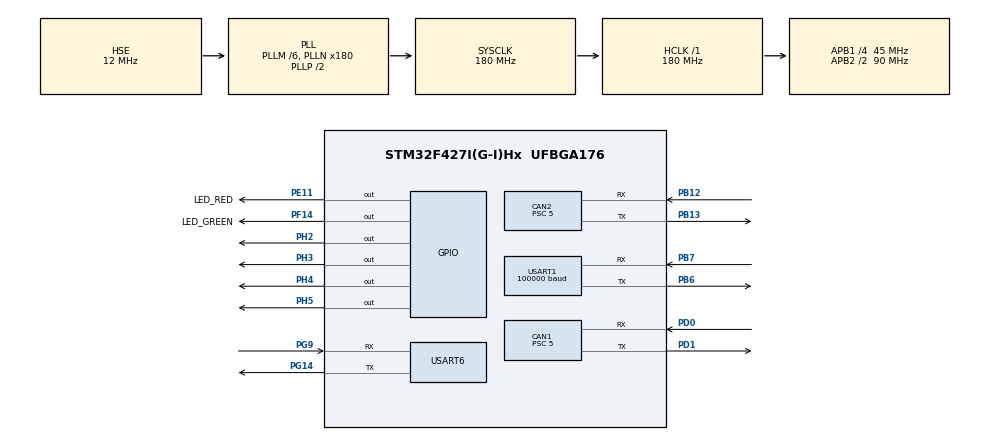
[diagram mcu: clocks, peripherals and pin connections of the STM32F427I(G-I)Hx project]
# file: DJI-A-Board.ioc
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CAN1.ABOM=ENABLE
CAN1.BS1=CAN_BS1_3TQ
CAN1.BS2=CAN_BS2_5TQ
CAN1.CalculateBaudRate=1000000
CAN1.CalculateTimeBit=1000
CAN1.CalculateTimeQuantum=111.11111111111111
CAN1.Prescaler=5
CAN2.ABOM=ENABLE
CAN2.BS1=CAN_BS1_3TQ
CAN2.BS2=CAN_BS2_5TQ
CAN2.CalculateBaudRate=1000000
CAN2.CalculateTimeBit=1000
CAN2.CalculateTimeQuantum=111.11111111111111
CAN2.Prescaler=5
Dma.Request0=USART1_RX
Dma.Request1=USART6_RX
Dma.Request2=USART6_TX
Dma.USART1_RX.0.Direction=DMA_PERIPH_TO_MEMORY
Dma.USART1_RX.0.FIFOMode=DMA_FIFOMODE_DISABLE
Dma.USART1_RX.0.Instance=DMA2_Stream2
Dma.USART1_RX.0.MemDataAlignment=DMA_MDATAALIGN_BYTE
Dma.USART1_RX.0.MemInc=DMA_MINC_ENABLE
Dma.USART1_RX.0.Mode=DMA_CIRCULAR
Dma.USART1_RX.0.PeriphDataAlignment=DMA_PDATAALIGN_BYTE
Dma.USART1_RX.0.PeriphInc=DMA_PINC_DISABLE
Dma.USART1_RX.0.Priority=DMA_PRIORITY_LOW
Dma.USART6_RX.1.Direction=DMA_PERIPH_TO_MEMORY
Dma.USART6_RX.1.FIFOMode=DMA_FIFOMODE_DISABLE
Dma.USART6_RX.1.Instance=DMA2_Stream1
Dma.USART6_RX.1.MemDataAlignment=DMA_MDATAALIGN_BYTE
Dma.USART6_RX.1.MemInc=DMA_MINC_ENABLE
Dma.USART6_RX.1.Mode=DMA_NORMAL
Dma.USART6_RX.1.PeriphDataAlignment=DMA_PDATAALIGN_BYTE
Dma.USART6_RX.1.PeriphInc=DMA_PINC_DISABLE
Dma.USART6_RX.1.Priority=DMA_PRIORITY_LOW
Dma.USART6_TX.2.Direction=DMA_MEMORY_TO_PERIPH
Dma.USART6_TX.2.FIFOMode=DMA_FIFOMODE_DISABLE
Dma.USART6_TX.2.Instance=DMA2_Stream6
Dma.USART6_TX.2.MemDataAlignment=DMA_MDATAALIGN_BYTE
Dma.USART6_TX.2.MemInc=DMA_MINC_ENABLE
Dma.USART6_TX.2.Mode=DMA_NORMAL
Dma.USART6_TX.2.PeriphDataAlignment=DMA_PDATAALIGN_BYTE
Dma.USART6_TX.2.PeriphInc=DMA_PINC_DISABLE
Dma.USART6_TX.2.Priority=DMA_PRIORITY_LOW
Mcu.Family=STM32F4
Mcu.Name=STM32F427I(G-I)Hx
Mcu.Package=UFBGA176
NVIC.CAN1_RX0_IRQn=true\:0\:0\:false\:false\:true\:true\:true\:true
NVIC.CAN2_RX0_IRQn=true\:0\:0\:false\:false\:true\:true\:true\:true
NVIC.DMA2_Stream1_IRQn=true\:0\:0\:false\:false\:true\:false\:true\:true
NVIC.DMA2_Stream2_IRQn=true\:0\:0\:false\:false\:true\:false\:true\:true
NVIC.DMA2_Stream6_IRQn=true\:0\:0\:false\:false\:true\:false\:true\:true
NVIC.PriorityGroup=NVIC_PRIORITYGROUP_4
NVIC.USART1_IRQn=true\:0\:0\:false\:false\:true\:true\:true\:true
NVIC.USART6_IRQn=true\:0\:0\:false\:false\:true\:true\:true\:true
PA13.Mode=Serial_Wire
PA13.Signal=SYS_JTMS-SWDIO
PA14.Mode=Serial_Wire
PA14.Signal=SYS_JTCK-SWCLK
PB12.Mode=CAN_Activate
PB12.Signal=CAN2_RX
PB13.Mode=CAN_Activate
PB13.Signal=CAN2_TX
PB6.GPIO_PuPd=GPIO_NOPULL
PB6.Mode=Asynchronous
PB6.Signal=USART1_TX
PB7.GPIO_PuPd=GPIO_NOPULL
PB7.Mode=Asynchronous
PB7.Signal=USART1_RX
PD0.Mode=CAN_Activate
PD0.Signal=CAN1_RX
PD1.Mode=CAN_Activate
PD1.Signal=CAN1_TX
PE11.GPIO_Label=LED_RED
PE11.GPIO_PuPd=GPIO_PULLUP
PE11.PinState=GPIO_PIN_SET
PE11.Signal=GPIO_Output
PF14.GPIO_Label=LED_GREEN
PF14.GPIO_PuPd=GPIO_PULLUP
PF14.PinState=GPIO_PIN_SET
PF14.Signal=GPIO_Output
PG14.GPIO_PuPd=GPIO_NOPULL
PG14.Mode=Asynchronous
PG14.Signal=USART6_TX
PG9.GPIO_PuPd=GPIO_NOPULL
PG9.Mode=Asynchronous
PG9.Signal=USART6_RX
PH0/OSC_IN.Mode=HSE-External-Oscillator
PH0/OSC_IN.Signal=RCC_OSC_IN
PH1/OSC_OUT.Mode=HSE-External-Oscillator
PH1/OSC_OUT.Signal=RCC_OSC_OUT
PH2.GPIO_PuPd=GPIO_PULLUP
PH2.PinState=GPIO_PIN_SET
PH2.Signal=GPIO_Output
PH3.GPIO_PuPd=GPIO_PULLUP
PH3.PinState=GPIO_PIN_SET
PH3.Signal=GPIO_Output
PH4.GPIO_PuPd=GPIO_PULLUP
PH4.PinState=GPIO_PIN_SET
PH4.Signal=GPIO_Output
PH5.GPIO_PuPd=GPIO_PULLUP
PH5.PinState=GPIO_PIN_SET
PH5.Signal=GPIO_Output
ProjectManager.HeapSize=0x200
ProjectManager.StackSize=0x400
ProjectManager.TargetToolchain=STM32CubeIDE
RCC.48MHZClocksFreq_Value=90000000
RCC.AHBFreq_Value=180000000
RCC.APB1CLKDivider=RCC_HCLK_DIV4
RCC.APB1Freq_Value=45000000
RCC.APB1TimFreq_Value=90000000
RCC.APB2CLKDivider=RCC_HCLK_DIV2
RCC.APB2Freq_Value=90000000
RCC.APB2TimFreq_Value=180000000
RCC.CortexFreq_Value=180000000
RCC.HCLKFreq_Value=180000000
RCC.HSE_VALUE=12000000
RCC.HSI_VALUE=16000000
RCC.LSE_VALUE=32768
RCC.PLLM=6
RCC.PLLN=180
RCC.PLLSourceVirtual=RCC_PLLSOURCE_HSE
RCC.SYSCLKFreq_VALUE=180000000
RCC.SYSCLKSource=RCC_SYSCLKSOURCE_PLLCLK
RCC.VCOOutputFreq_Value=360000000
TIM14.Period=10000-1
TIM14.Prescaler=45000-1
USART1.BaudRate=100000
USART1.Mode=MODE_TX_RX
USART1.Parity=PARITY_EVEN
USART1.VirtualMode=VM_ASYNC
USART6.VirtualMode=VM_ASYNC
VP_TIM14_VS_ClockSourceINT.Mode=Enable_Timer
board=custom

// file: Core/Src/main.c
/* USER CODE BEGIN Header */
/**
  ******************************************************************************
  * @file           : main.c
  * @brief          : Main program body
  ******************************************************************************
  * @attention
  *
  * Copyright (c) 2025 STMicroelectronics.
  * All rights reserved.
  *
  * This software is licensed under terms that can be found in the LICENSE file
  * in the root directory of this software component.
  * If no LICENSE file comes with this software, it is provided AS-IS.
  *
  ******************************************************************************
  */
/* USER CODE END Header */
#include "main.h"

/* USER CODE BEGIN Includes */
#include  "bsp.h"
#include <stdio.h>

/* USER CODE END Includes */

CAN_HandleTypeDef hcan1;
CAN_HandleTypeDef hcan2;

TIM_HandleTypeDef htim14;

UART_HandleTypeDef huart1;
UART_HandleTypeDef huart6;
DMA_HandleTypeDef hdma_usart1_rx;
DMA_HandleTypeDef hdma_usart6_rx;
DMA_HandleTypeDef hdma_usart6_tx;

void SystemClock_Config(void);
static void MX_GPIO_Init(void);
static void MX_DMA_Init(void);
static void MX_USART1_UART_Init(void);
static void MX_USART6_UART_Init(void);
static void MX_CAN1_Init(void);
static void MX_TIM14_Init(void);
static void MX_CAN2_Init(void);

int main(void)
{

  /* MCU Configuration--------------------------------------------------------*/

  /* Reset of all peripherals, Initializes the Flash interface and the Systick. */
  HAL_Init();

  /* Configure the system clock */
  SystemClock_Config();

  /* Initialize all configured peripherals */
  MX_GPIO_Init();
  MX_DMA_Init();
  MX_USART1_UART_Init();
  MX_USART6_UART_Init();
  MX_CAN1_Init();
  MX_TIM14_Init();
  MX_CAN2_Init();

  /* Infinite loop */
  while (1)
  {

    /* USER CODE BEGIN 3 */
    LOOP_EVENT_Handle();
  }
  /* USER CODE END 3 */
}

void SystemClock_Config(void)
{
  RCC_OscInitTypeDef RCC_OscInitStruct = {0};
  RCC_ClkInitTypeDef RCC_ClkInitStruct = {0};

  /** Configure the main internal regulator output voltage
  */
  __HAL_RCC_PWR_CLK_ENABLE();
  __HAL_PWR_VOLTAGESCALING_CONFIG(PWR_REGULATOR_VOLTAGE_SCALE1);

  /** Initializes the RCC Oscillators according to the specified parameters
  * in the RCC_OscInitTypeDef structure.
  */
  RCC_OscInitStruct.OscillatorType = RCC_OSCILLATORTYPE_HSE;
  RCC_OscInitStruct.HSEState = RCC_HSE_ON;
  RCC_OscInitStruct.PLL.PLLState = RCC_PLL_ON;
  RCC_OscInitStruct.PLL.PLLSource = RCC_PLLSOURCE_HSE;
  RCC_OscInitStruct.PLL.PLLM = 6;
  RCC_OscInitStruct.PLL.PLLN = 180;
  RCC_OscInitStruct.PLL.PLLP = RCC_PLLP_DIV2;
  RCC_OscInitStruct.PLL.PLLQ = 4;
  if (HAL_RCC_OscConfig(&RCC_OscInitStruct) != HAL_OK)
  {
    Error_Handler();
  }

  /** Activate the Over-Drive mode
  */
  if (HAL_PWREx_EnableOverDrive() != HAL_OK)
  {
    Error_Handler();
  }

  /** Initializes the CPU, AHB and APB buses clocks
  */
  RCC_ClkInitStruct.ClockType = RCC_CLOCKTYPE_HCLK|RCC_CLOCKTYPE_SYSCLK
                              |RCC_CLOCKTYPE_PCLK1|RCC_CLOCKTYPE_PCLK2;
  RCC_ClkInitStruct.SYSCLKSource = RCC_SYSCLKSOURCE_PLLCLK;
  RCC_ClkInitStruct.AHBCLKDivider = RCC_SYSCLK_DIV1;
  RCC_ClkInitStruct.APB1CLKDivider = RCC_HCLK_DIV4;
  RCC_ClkInitStruct.APB2CLKDivider = RCC_HCLK_DIV2;

  if (HAL_RCC_ClockConfig(&RCC_ClkInitStruct, FLASH_LATENCY_5) != HAL_OK)
  {
    Error_Handler();
  }
}

static void MX_CAN1_Init(void)
{

  hcan1.Instance = CAN1;
  hcan1.Init.Prescaler = 5;
  hcan1.Init.Mode = CAN_MODE_NORMAL;
  hcan1.Init.SyncJumpWidth = CAN_SJW_1TQ;
  hcan1.Init.TimeSeg1 = CAN_BS1_3TQ;
  hcan1.Init.TimeSeg2 = CAN_BS2_5TQ;
  hcan1.Init.TimeTriggeredMode = DISABLE;
  hcan1.Init.AutoBusOff = ENABLE;
  hcan1.Init.AutoWakeUp = DISABLE;
  hcan1.Init.AutoRetransmission = DISABLE;
  hcan1.Init.ReceiveFifoLocked = DISABLE;
  hcan1.Init.TransmitFifoPriority = DISABLE;
  if (HAL_CAN_Init(&hcan1) != HAL_OK)
  {
    Error_Handler();
  }

}

static void MX_CAN2_Init(void)
{

  hcan2.Instance = CAN2;
  hcan2.Init.Prescaler = 5;
  hcan2.Init.Mode = CAN_MODE_NORMAL;
  hcan2.Init.SyncJumpWidth = CAN_SJW_1TQ;
  hcan2.Init.TimeSeg1 = CAN_BS1_3TQ;
  hcan2.Init.TimeSeg2 = CAN_BS2_5TQ;
  hcan2.Init.TimeTriggeredMode = DISABLE;
  hcan2.Init.AutoBusOff = ENABLE;
  hcan2.Init.AutoWakeUp = DISABLE;
  hcan2.Init.AutoRetransmission = DISABLE;
  hcan2.Init.ReceiveFifoLocked = DISABLE;
  hcan2.Init.TransmitFifoPriority = DISABLE;
  if (HAL_CAN_Init(&hcan2) != HAL_OK)
  {
    Error_Handler();
  }

}

static void MX_TIM14_Init(void)
{

  htim14.Instance = TIM14;
  htim14.Init.Prescaler = 45000-1;
  htim14.Init.CounterMode = TIM_COUNTERMODE_UP;
  htim14.Init.Period = 10000-1;
  htim14.Init.ClockDivision = TIM_CLOCKDIVISION_DIV1;
  htim14.Init.AutoReloadPreload = TIM_AUTORELOAD_PRELOAD_DISABLE;
  if (HAL_TIM_Base_Init(&htim14) != HAL_OK)
  {
    Error_Handler();
  }

}

static void MX_USART1_UART_Init(void)
{

  huart1.Instance = USART1;
  huart1.Init.BaudRate = 100000;
  huart1.Init.WordLength = UART_WORDLENGTH_8B;
  huart1.Init.StopBits = UART_STOPBITS_1;
  huart1.Init.Parity = UART_PARITY_EVEN;
  huart1.Init.Mode = UART_MODE_TX_RX;
  huart1.Init.HwFlowCtl = UART_HWCONTROL_NONE;
  huart1.Init.OverSampling = UART_OVERSAMPLING_16;
  if (HAL_UART_Init(&huart1) != HAL_OK)
  {
    Error_Handler();
  }

}

static void MX_USART6_UART_Init(void)
{

  huart6.Instance = USART6;
  huart6.Init.BaudRate = 115200;
  huart6.Init.WordLength = UART_WORDLENGTH_8B;
  huart6.Init.StopBits = UART_STOPBITS_1;
  huart6.Init.Parity = UART_PARITY_NONE;
  huart6.Init.Mode = UART_MODE_TX_RX;
  huart6.Init.HwFlowCtl = UART_HWCONTROL_NONE;
  huart6.Init.OverSampling = UART_OVERSAMPLING_16;
  if (HAL_UART_Init(&huart6) != HAL_OK)
  {
    Error_Handler();
  }

}

static void MX_DMA_Init(void)
{

  /* DMA controller clock enable */
  __HAL_RCC_DMA2_CLK_ENABLE();

  /* DMA interrupt init */
  /* DMA2_Stream1_IRQn interrupt configuration */
  HAL_NVIC_SetPriority(DMA2_Stream1_IRQn, 0, 0);
  HAL_NVIC_EnableIRQ(DMA2_Stream1_IRQn);
  /* DMA2_Stream2_IRQn interrupt configuration */
  HAL_NVIC_SetPriority(DMA2_Stream2_IRQn, 0, 0);
  HAL_NVIC_EnableIRQ(DMA2_Stream2_IRQn);
  /* DMA2_Stream6_IRQn interrupt configuration */
  HAL_NVIC_SetPriority(DMA2_Stream6_IRQn, 0, 0);
  HAL_NVIC_EnableIRQ(DMA2_Stream6_IRQn);

}

static void MX_GPIO_Init(void)
{
  GPIO_InitTypeDef GPIO_InitStruct = {0};

  /* GPIO Ports Clock Enable */
  __HAL_RCC_GPIOG_CLK_ENABLE();
  __HAL_RCC_GPIOA_CLK_ENABLE();
  __HAL_RCC_GPIOB_CLK_ENABLE();
  __HAL_RCC_GPIOD_CLK_ENABLE();
  __HAL_RCC_GPIOH_CLK_ENABLE();
  __HAL_RCC_GPIOE_CLK_ENABLE();
  __HAL_RCC_GPIOF_CLK_ENABLE();

  /*Configure GPIO pin Output Level */
  HAL_GPIO_WritePin(GPIOH, GPIO_PIN_2|GPIO_PIN_3|GPIO_PIN_4|GPIO_PIN_5, GPIO_PIN_SET);

  /*Configure GPIO pin Output Level */
  HAL_GPIO_WritePin(LED_RED_GPIO_Port, LED_RED_Pin, GPIO_PIN_SET);

  /*Configure GPIO pin Output Level */
  HAL_GPIO_WritePin(LED_GREEN_GPIO_Port, LED_GREEN_Pin, GPIO_PIN_SET);

  /*Configure GPIO pins : PH2 PH3 PH4 PH5 */
  GPIO_InitStruct.Pin = GPIO_PIN_2|GPIO_PIN_3|GPIO_PIN_4|GPIO_PIN_5;
  GPIO_InitStruct.Mode = GPIO_MODE_OUTPUT_PP;
  GPIO_InitStruct.Pull = GPIO_PULLUP;
  GPIO_InitStruct.Speed = GPIO_SPEED_FREQ_LOW;
  HAL_GPIO_Init(GPIOH, &GPIO_InitStruct);

  /*Configure GPIO pin : LED_RED_Pin */
  GPIO_InitStruct.Pin = LED_RED_Pin;
  GPIO_InitStruct.Mode = GPIO_MODE_OUTPUT_PP;
  GPIO_InitStruct.Pull = GPIO_PULLUP;
  GPIO_InitStruct.Speed = GPIO_SPEED_FREQ_LOW;
  HAL_GPIO_Init(LED_RED_GPIO_Port, &GPIO_InitStruct);

  /*Configure GPIO pin : LED_GREEN_Pin */
  GPIO_InitStruct.Pin = LED_GREEN_Pin;
  GPIO_InitStruct.Mode = GPIO_MODE_OUTPUT_PP;
  GPIO_InitStruct.Pull = GPIO_PULLUP;
  GPIO_InitStruct.Speed = GPIO_SPEED_FREQ_LOW;
  HAL_GPIO_Init(LED_GREEN_GPIO_Port, &GPIO_InitStruct);

}

void Error_Handler(void)
{
  __disable_irq();
  while (1)
  {
  }
}
